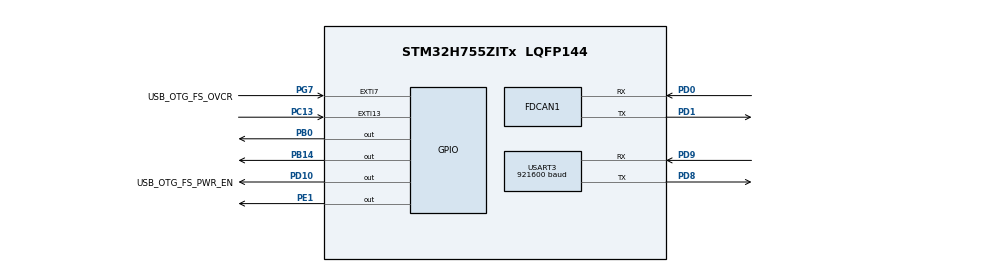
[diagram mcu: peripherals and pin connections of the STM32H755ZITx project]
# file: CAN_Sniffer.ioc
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CortexM4.IPs=FATFS_M4\:I,FREERTOS_M4\:I,IWDG2\:I,RCC,WWDG2\:I,DMA,BDMA,MDMA,NVIC2\:I,PDM2PCM_M4\:I,PWR,RESMGR_UTILITY,SYS_M4\:I,USB_DEVICE_M4\:I,USB_HOST_M4\:I,CORTEX_M4\:I,GPIO,OPENAMP_M4\:I,VREFBUF
CortexM7.IPs=FATFS_M7\:I,FREERTOS_M7\:I,IWDG1\:I,RCC\:I,WWDG1\:I,DMA\:I,BDMA\:I,MDMA\:I,NVIC1\:I,USART3\:I,SYS\:I,CORTEX_M7\:I,PDM2PCM_M7\:I,PWR\:I,RESMGR_UTILITY\:I,USB_DEVICE_M7\:I,USB_HOST_M7\:I,GPIO\:I,OPENAMP_M7\:I,VREFBUF\:I,MEMORYMAP\:I,FDCAN1\:I
CortexM7.Pins=PC13
FDCAN1.CalculateBaudRateNominal=5000
FDCAN1.CalculateTimeBitNominal=200000
FDCAN1.CalculateTimeQuantumNominal=5000.0
FDCAN1.Mode=FDCAN_MODE_BUS_MONITORING
FDCAN1.NominalPrescaler=200
FDCAN1.NominalSyncJumpWidth=2
FDCAN1.NominalTimeSeg1=34
FDCAN1.NominalTimeSeg2=5
FDCAN1.ProtocolException=ENABLE
FDCAN1.RxFifo0ElmtsNbr=64
FDCAN1.StdFiltersNbr=1
Mcu.Family=STM32H7
Mcu.Name=STM32H755ZITx
Mcu.Package=LQFP144
NVIC1.EXTI15_10_IRQn=true\:0\:0\:false\:false\:true\:true\:true\:true
NVIC1.FDCAN1_IT0_IRQn=true\:0\:0\:false\:false\:true\:true\:true\:true
NVIC1.PriorityGroup=NVIC_PRIORITYGROUP_4
NVIC2.PriorityGroup=NVIC_PRIORITYGROUP_4
PA1.PinAttribute=CortexM4
PA1.Signal=ETH_REF_CLK
PA11.PinAttribute=CortexM7
PA11.Signal=USB_OTG_FS_DM
PA12.PinAttribute=CortexM7
PA12.Signal=USB_OTG_FS_DP
PA2.PinAttribute=CortexM4
PA2.Signal=ETH_MDIO
PA7.PinAttribute=CortexM4
PA7.Signal=ETH_CRS_DV
PA8.PinAttribute=CortexM7
PA8.Signal=USB_OTG_FS_SOF
PA9.PinAttribute=CortexM7
PA9.Signal=USB_OTG_FS_VBUS
PB0.PinAttribute=Free
PB0.Signal=GPIO_Output
PB13.PinAttribute=CortexM4
PB13.Signal=ETH_TXD1
PB14.PinAttribute=Free
PB14.Signal=GPIO_Output
PC1.PinAttribute=CortexM4
PC1.Signal=ETH_MDC
PC13.GPIO_PuPd=GPIO_PULLDOWN
PC13.PinAttribute=CortexM7
PC13.Signal=GPXTI13
PC14-OSC32_IN\ (OSC32_IN).PinAttribute=Free
PC14-OSC32_IN\ (OSC32_IN).Signal=RCC_OSC32_IN
PC15-OSC32_OUT\ (OSC32_OUT).PinAttribute=Free
PC15-OSC32_OUT\ (OSC32_OUT).Signal=RCC_OSC32_OUT
PC4.PinAttribute=CortexM4
PC4.Signal=ETH_RXD0
PC5.PinAttribute=CortexM4
PC5.Signal=ETH_RXD1
PD0.Mode=FDCAN_Activate
PD0.PinAttribute=CortexM7
PD0.Signal=FDCAN1_RX
PD1.Mode=FDCAN_Activate
PD1.PinAttribute=CortexM7
PD1.Signal=FDCAN1_TX
PD10.GPIO_Label=USB_OTG_FS_PWR_EN
PD10.PinAttribute=Free
PD10.Signal=GPIO_Output
PD8.Mode=Asynchronous
PD8.PinAttribute=CortexM7
PD8.Signal=USART3_TX
PD9.Mode=Asynchronous
PD9.PinAttribute=CortexM7
PD9.Signal=USART3_RX
PE1.PinAttribute=Free
PE1.Signal=GPIO_Output
PG11.PinAttribute=CortexM4
PG11.Signal=ETH_TX_EN
PG13.PinAttribute=CortexM4
PG13.Signal=ETH_TXD0
PG7.GPIO_Label=USB_OTG_FS_OVCR
PG7.PinAttribute=Free
PG7.Signal=GPXTI7
PH0-OSC_IN\ (PH0).PinAttribute=Free
PH0-OSC_IN\ (PH0).Signal=RCC_OSC_IN
PH1-OSC_OUT\ (PH1).PinAttribute=Free
PH1-OSC_OUT\ (PH1).Signal=RCC_OSC_OUT
ProjectManager.HeapSize=M4-0x200,M7-0x200
ProjectManager.StackSize=M4-0x400,M7-0x400
ProjectManager.TargetToolchain=STM32CubeIDE
RCC.ADCFreq_Value=80000000
RCC.APB1Freq_Value=32000000
RCC.APB2Freq_Value=64000000
RCC.APB3Freq_Value=64000000
RCC.APB4Freq_Value=64000000
RCC.CortexFreq_Value=64000000
RCC.D2PPRE1=RCC_APB1_DIV2
RCC.DIVM1=5
RCC.DIVM2=4
RCC.DIVN1=48
RCC.DIVN2=10
RCC.DIVQ1=5
RCC.DIVQ2=4
RCC.FDCANCLockSelection=RCC_FDCANCLKSOURCE_PLL2
RCC.HCLKFreq_Value=64000000
RCC.PLL2FRACN=0
RCC.PLL3FRACN=0
RCC.PLLFRACN=0
RCC.SYSCLKFreq_VALUE=64000000
RCC.SupplySource=PWR_DIRECT_SMPS_SUPPLY
RCC.USBFreq_Value=122880000
USART3.BaudRate=921600
USART3.DMADisableonRxErrorParam=ADVFEATURE_DMA_DISABLEONRXERROR
USART3.FIFOMode=FIFOMODE_ENABLE
USART3.OverrunDisableParam=ADVFEATURE_OVERRUN_DISABLE
USART3.VirtualMode-Asynchronous=VM_ASYNC
VP_MEMORYMAP_VS_MEMORYMAP.Mode=CurAppReg
VP_SYS_M4_VS_Systick.Mode=SysTick
board=NUCLEO-H755ZI-Q

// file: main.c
/* USER CODE BEGIN Header */
/**
 * @file main.c
 * @brief Main program body for the CAN sniffer firmware.
 *
 * @details
 * Contains the infinite main loop that switches between:
 *   - Capturing and sending CAN frames (STATE_RUN)
 *   - Entering the settings menu (STATE_MENU)
 *
 * The user can press the User Button (PC13) to force menu entry asynchronously.
 */
/* USER CODE END Header */
#include "main.h"

/* USER CODE BEGIN Includes */
#include "settings_menu.h"
/* USER CODE END Includes */

/* USER CODE BEGIN PD */

/* DUAL_CORE_BOOT_SYNC_SEQUENCE: Define for dual core boot synchronization    */
/*                             demonstration code based on hardware semaphore */
/* This define is present in both CM7/CM4 projects                            */
/* To comment when developping/debugging on a single core                     */
//#define DUAL_CORE_BOOT_SYNC_SEQUENCE

#if defined(DUAL_CORE_BOOT_SYNC_SEQUENCE)
#ifndef HSEM_ID_0
#define HSEM_ID_0 (0U) /* HW semaphore 0*/
#endif
#endif /* DUAL_CORE_BOOT_SYNC_SEQUENCE */

/* USER CODE END PD */

FDCAN_HandleTypeDef hfdcan1;

UART_HandleTypeDef huart3;

void SystemClock_Config(void);
static void MX_GPIO_Init(void);
static void MX_FDCAN1_Init(void);
static void MX_USART3_UART_Init(void);

int main(void)
{

/* USER CODE BEGIN Boot_Mode_Sequence_0 */
#if defined(DUAL_CORE_BOOT_SYNC_SEQUENCE)
  int32_t timeout;
#endif /* DUAL_CORE_BOOT_SYNC_SEQUENCE */
/* USER CODE END Boot_Mode_Sequence_0 */

/* USER CODE BEGIN Boot_Mode_Sequence_1 */
#if defined(DUAL_CORE_BOOT_SYNC_SEQUENCE)
  /* Wait until CPU2 boots and enters in stop mode or timeout*/
  timeout = 0xFFFF;
  while((__HAL_RCC_GET_FLAG(RCC_FLAG_D2CKRDY) != RESET) && (timeout-- > 0));
  if ( timeout < 0 )
  {
  Error_Handler();
  }
#endif /* DUAL_CORE_BOOT_SYNC_SEQUENCE */
/* USER CODE END Boot_Mode_Sequence_1 */
  /* MCU Configuration--------------------------------------------------------*/

  /* Reset of all peripherals, Initializes the Flash interface and the Systick. */
  HAL_Init();

  /* Configure the system clock */
  SystemClock_Config();
/* USER CODE BEGIN Boot_Mode_Sequence_2 */
#if defined(DUAL_CORE_BOOT_SYNC_SEQUENCE)
/* When system initialization is finished, Cortex-M7 will release Cortex-M4 by means of
HSEM notification */
/*HW semaphore Clock enable*/
__HAL_RCC_HSEM_CLK_ENABLE();
/*Take HSEM */
HAL_HSEM_FastTake(HSEM_ID_0);
/*Release HSEM in order to notify the CPU2(CM4)*/
HAL_HSEM_Release(HSEM_ID_0,0);
/* wait until CPU2 wakes up from stop mode */
timeout = 0xFFFF;
while((__HAL_RCC_GET_FLAG(RCC_FLAG_D2CKRDY) == RESET) && (timeout-- > 0));
if ( timeout < 0 )
{
Error_Handler();
}
#endif /* DUAL_CORE_BOOT_SYNC_SEQUENCE */
/* USER CODE END Boot_Mode_Sequence_2 */

  /* Initialize all configured peripherals */
  MX_GPIO_Init();
  MX_FDCAN1_Init();
  MX_USART3_UART_Init();

  /* Infinite loop */
  /* USER CODE BEGIN WHILE */
  /**
   * @brief Main firmware loop.
   *
   * @details
   * Continuously polls the system_state variable:
   *   - If STATE_RUN: captures and sends CAN frames over UART.
   *   - If STATE_MENU: enters the blocking settings menu to configure CAN.
   *
   * This loop runs indefinitely.
   */
  while (1)
  {
	  if (system_state == STATE_RUN) {
		  /* Capture CAN frames from buffer and send via UART */
		  send_frame_over_UART();
	  } else {
		  settings_menu();
	  }
    /* USER CODE END WHILE */

  }
}

void SystemClock_Config(void)
{
  RCC_OscInitTypeDef RCC_OscInitStruct = {0};
  RCC_ClkInitTypeDef RCC_ClkInitStruct = {0};

  /** Supply configuration update enable
  */
  HAL_PWREx_ConfigSupply(PWR_DIRECT_SMPS_SUPPLY);

  /** Configure the main internal regulator output voltage
  */
  __HAL_PWR_VOLTAGESCALING_CONFIG(PWR_REGULATOR_VOLTAGE_SCALE3);

  while(!__HAL_PWR_GET_FLAG(PWR_FLAG_VOSRDY)) {}

  /** Macro to configure the PLL clock source
  */
  __HAL_RCC_PLL_PLLSOURCE_CONFIG(RCC_PLLSOURCE_HSI);

  /** Initializes the RCC Oscillators according to the specified parameters
  * in the RCC_OscInitTypeDef structure.
  */
  RCC_OscInitStruct.OscillatorType = RCC_OSCILLATORTYPE_HSI;
  RCC_OscInitStruct.HSIState = RCC_HSI_DIV1;
  RCC_OscInitStruct.HSICalibrationValue = RCC_HSICALIBRATION_DEFAULT;
  RCC_OscInitStruct.PLL.PLLState = RCC_PLL_NONE;
  if (HAL_RCC_OscConfig(&RCC_OscInitStruct) != HAL_OK)
  {
    Error_Handler();
  }

  /** Initializes the CPU, AHB and APB buses clocks
  */
  RCC_ClkInitStruct.ClockType = RCC_CLOCKTYPE_HCLK|RCC_CLOCKTYPE_SYSCLK
                              |RCC_CLOCKTYPE_PCLK1|RCC_CLOCKTYPE_PCLK2
                              |RCC_CLOCKTYPE_D3PCLK1|RCC_CLOCKTYPE_D1PCLK1;
  RCC_ClkInitStruct.SYSCLKSource = RCC_SYSCLKSOURCE_HSI;
  RCC_ClkInitStruct.SYSCLKDivider = RCC_SYSCLK_DIV1;
  RCC_ClkInitStruct.AHBCLKDivider = RCC_HCLK_DIV1;
  RCC_ClkInitStruct.APB3CLKDivider = RCC_APB3_DIV1;
  RCC_ClkInitStruct.APB1CLKDivider = RCC_APB1_DIV2;
  RCC_ClkInitStruct.APB2CLKDivider = RCC_APB2_DIV1;
  RCC_ClkInitStruct.APB4CLKDivider = RCC_APB4_DIV1;

  if (HAL_RCC_ClockConfig(&RCC_ClkInitStruct, FLASH_LATENCY_1) != HAL_OK)
  {
    Error_Handler();
  }
}

static void MX_FDCAN1_Init(void)
{

  hfdcan1.Instance = FDCAN1;
  hfdcan1.Init.FrameFormat = FDCAN_FRAME_CLASSIC;
  hfdcan1.Init.Mode = FDCAN_MODE_BUS_MONITORING;
  hfdcan1.Init.AutoRetransmission = DISABLE;
  hfdcan1.Init.TransmitPause = DISABLE;
  hfdcan1.Init.ProtocolException = ENABLE;
  hfdcan1.Init.NominalPrescaler = 200;
  hfdcan1.Init.NominalSyncJumpWidth = 2;
  hfdcan1.Init.NominalTimeSeg1 = 34;
  hfdcan1.Init.NominalTimeSeg2 = 5;
  hfdcan1.Init.DataPrescaler = 1;
  hfdcan1.Init.DataSyncJumpWidth = 1;
  hfdcan1.Init.DataTimeSeg1 = 1;
  hfdcan1.Init.DataTimeSeg2 = 1;
  hfdcan1.Init.MessageRAMOffset = 0;
  hfdcan1.Init.StdFiltersNbr = 1;
  hfdcan1.Init.ExtFiltersNbr = 0;
  hfdcan1.Init.RxFifo0ElmtsNbr = 64;
  hfdcan1.Init.RxFifo0ElmtSize = FDCAN_DATA_BYTES_8;
  hfdcan1.Init.RxFifo1ElmtsNbr = 0;
  hfdcan1.Init.RxFifo1ElmtSize = FDCAN_DATA_BYTES_8;
  hfdcan1.Init.RxBuffersNbr = 0;
  hfdcan1.Init.RxBufferSize = FDCAN_DATA_BYTES_8;
  hfdcan1.Init.TxEventsNbr = 0;
  hfdcan1.Init.TxBuffersNbr = 0;
  hfdcan1.Init.TxFifoQueueElmtsNbr = 0;
  hfdcan1.Init.TxFifoQueueMode = FDCAN_TX_FIFO_OPERATION;
  hfdcan1.Init.TxElmtSize = FDCAN_DATA_BYTES_8;
  if (HAL_FDCAN_Init(&hfdcan1) != HAL_OK)
  {
    Error_Handler();
  }

}

static void MX_USART3_UART_Init(void)
{

  huart3.Instance = USART3;
  huart3.Init.BaudRate = 921600;
  huart3.Init.WordLength = UART_WORDLENGTH_8B;
  huart3.Init.StopBits = UART_STOPBITS_1;
  huart3.Init.Parity = UART_PARITY_NONE;
  huart3.Init.Mode = UART_MODE_TX_RX;
  huart3.Init.HwFlowCtl = UART_HWCONTROL_NONE;
  huart3.Init.OverSampling = UART_OVERSAMPLING_16;
  huart3.Init.OneBitSampling = UART_ONE_BIT_SAMPLE_DISABLE;
  huart3.Init.ClockPrescaler = UART_PRESCALER_DIV1;
  huart3.AdvancedInit.AdvFeatureInit = UART_ADVFEATURE_RXOVERRUNDISABLE_INIT|UART_ADVFEATURE_DMADISABLEONERROR_INIT;
  huart3.AdvancedInit.OverrunDisable = UART_ADVFEATURE_OVERRUN_DISABLE;
  huart3.AdvancedInit.DMADisableonRxError = UART_ADVFEATURE_DMA_DISABLEONRXERROR;
  if (HAL_UART_Init(&huart3) != HAL_OK)
  {
    Error_Handler();
  }
  if (HAL_UARTEx_SetTxFifoThreshold(&huart3, UART_TXFIFO_THRESHOLD_1_8) != HAL_OK)
  {
    Error_Handler();
  }
  if (HAL_UARTEx_SetRxFifoThreshold(&huart3, UART_RXFIFO_THRESHOLD_1_8) != HAL_OK)
  {
    Error_Handler();
  }
  if (HAL_UARTEx_EnableFifoMode(&huart3) != HAL_OK)
  {
    Error_Handler();
  }

}

static void MX_GPIO_Init(void)
{
  GPIO_InitTypeDef GPIO_InitStruct = {0};

  /* GPIO Ports Clock Enable */
  __HAL_RCC_GPIOC_CLK_ENABLE();
  __HAL_RCC_GPIOD_CLK_ENABLE();
  __HAL_RCC_GPIOA_CLK_ENABLE();

  /*Configure GPIO pin : PC13 */
  GPIO_InitStruct.Pin = GPIO_PIN_13;
  GPIO_InitStruct.Mode = GPIO_MODE_IT_RISING;
  GPIO_InitStruct.Pull = GPIO_PULLDOWN;
  HAL_GPIO_Init(GPIOC, &GPIO_InitStruct);

  /*Configure GPIO pins : PA8 PA11 PA12 */
  GPIO_InitStruct.Pin = GPIO_PIN_8|GPIO_PIN_11|GPIO_PIN_12;
  GPIO_InitStruct.Mode = GPIO_MODE_AF_PP;
  GPIO_InitStruct.Pull = GPIO_NOPULL;
  GPIO_InitStruct.Speed = GPIO_SPEED_FREQ_LOW;
  GPIO_InitStruct.Alternate = GPIO_AF10_OTG1_FS;
  HAL_GPIO_Init(GPIOA, &GPIO_InitStruct);

  /* EXTI interrupt init*/
  HAL_NVIC_SetPriority(EXTI15_10_IRQn, 0, 0);
  HAL_NVIC_EnableIRQ(EXTI15_10_IRQn);

}

/* USER CODE BEGIN 4 */
/**
 * @fn void HAL_GPIO_EXTI_Callback(uint16_t GPIO_Pin)
 * @brief External interrupt callback for GPIO pins.
 *
 * @param GPIO_Pin The pin number that triggered the interrupt.
 * @retval None
 *
 * @details
 * If the User Button (PC13) is pressed, this callback sets
 * the global system_state to STATE_MENU, forcing the main loop
 * to enter the settings menu on the next iteration.
 *
 * This allows the user to re-enter the menu at any time.
 */
void HAL_GPIO_EXTI_Callback(uint16_t GPIO_Pin) {
	if (GPIO_Pin == GPIO_PIN_13) {
		system_state = STATE_MENU;
	}
}
/* USER CODE END 4 */

void Error_Handler(void)
{
  __disable_irq();
  while (1)
  {
  }
}
